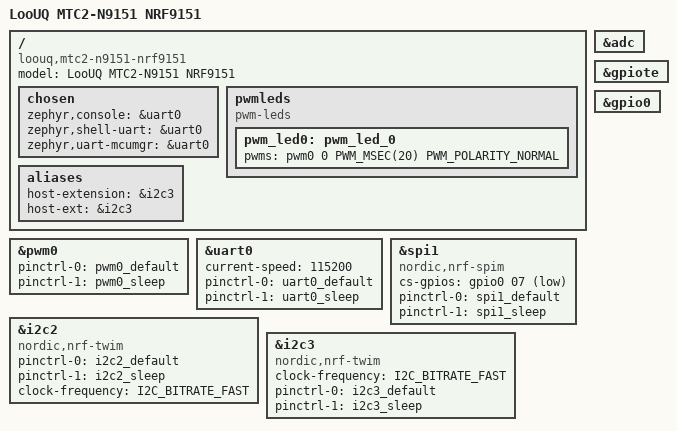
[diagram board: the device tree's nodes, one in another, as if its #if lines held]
/*
 * Copyright (c) 2023 Nordic Semiconductor ASA
 * Copyright (c) 2025 LooUQ Incorporated
 *
 * SPDX-License-Identifier: Apache-2.0
 */
#include "mtc2n9151_nrf9151_common-pinctrl.dtsi"
#include <zephyr/dt-bindings/input/input-event-codes.h>

/ {
	model = "LooUQ MTC2-N9151 NRF9151";
	compatible = "loouq,mtc2-n9151-nrf9151";

	chosen {
		zephyr,console = &uart0;
		zephyr,shell-uart = &uart0;
		zephyr,uart-mcumgr = &uart0;
	};

	pwmleds {
		compatible = "pwm-leds";
		pwm_led0: pwm_led_0 {
			pwms = <&pwm0 0 PWM_MSEC(20) PWM_POLARITY_NORMAL>;
		};
	};

    aliases {
        host-extension = &i2c3;
        host-ext = &i2c3;
    };

};

&pwm0 {
	status = "okay";
	pinctrl-0 = <&pwm0_default>;
	pinctrl-1 = <&pwm0_sleep>;
	pinctrl-names = "default", "sleep";
};

&adc {
	status = "okay";
};

&gpiote {
	status = "okay";
};

&gpio0 {
	status = "okay";
};

&uart0 {
	status = "okay";
	current-speed = <115200>;
	pinctrl-0 = <&uart0_default>;
	pinctrl-1 = <&uart0_sleep>;
	pinctrl-names = "default", "sleep";
};

/* Application SPI */
&spi1 {
 	compatible = "nordic,nrf-spim";
 	status = "okay";
    cs-gpios = <&gpio0 07 GPIO_ACTIVE_LOW>;
	pinctrl-0 = <&spi1_default>;
	pinctrl-1 = <&spi1_sleep>;
	pinctrl-names = "default", "sleep";
};

&i2c2 {
   	compatible = "nordic,nrf-twim";
	status = "okay";
	pinctrl-0 = <&i2c2_default>;
	pinctrl-1 = <&i2c2_sleep>;
	pinctrl-names = "default", "sleep";
	clock-frequency = <I2C_BITRATE_FAST>;
};

/* Host Extension I2C pins: supports 
 * RGB LED indicator and peripheral MTC2 multiplexor
 */
&i2c3 {
 	compatible = "nordic,nrf-twim";
 	status = "okay";
    clock-frequency = <I2C_BITRATE_FAST>;

	pinctrl-0 = <&i2c3_default>;
	pinctrl-1 = <&i2c3_sleep>;
	pinctrl-names = "default", "sleep";
};


/* Include default memory partition configuration file
   NOTE: the location changed in NCS version 3.1.0 (and after)
   <your_ncs>\v3.0.2\zephyr\dts\common\nordic 
   was moved to
   <your_ncs>\v3.1.1\zephyr\dts\vendor\nordic
*/
#if __has_include("common/nordic/nrf91xx_partition.dtsi")
    #include <common/nordic/nrf91xx_partition.dtsi>
#else
    #include <vendor/nordic/nrf91xx_partition.dtsi>
#endif
